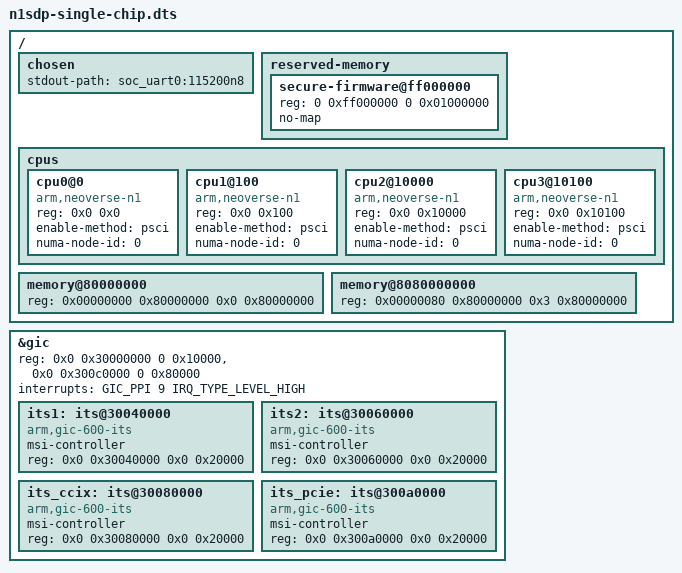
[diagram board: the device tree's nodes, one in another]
/*
 * Copyright (c) 2020, Arm Limited. All rights reserved.
 *
 * SPDX-License-Identifier: BSD-3-Clause
 */

/dts-v1/;

#include "n1sdp.dtsi"

/ {

	chosen {
		stdout-path = "soc_uart0:115200n8";
	};

	reserved-memory {
		#address-cells = <2>;
		#size-cells = <2>;
		ranges;

		secure-firmware@ff000000 {
			reg = <0 0xff000000 0 0x01000000>;
			no-map;
		};
	};

	cpus {
		#address-cells = <2>;
		#size-cells = <0>;
		cpu0@0 {
			compatible = "arm,neoverse-n1";
			reg = <0x0 0x0>;
			device_type = "cpu";
			enable-method = "psci";
			/* node 0 */
			numa-node-id = <0>;
		};
		cpu1@100 {
			compatible = "arm,neoverse-n1";
			reg = <0x0 0x100>;
			device_type = "cpu";
			enable-method = "psci";
			/* node 0 */
			numa-node-id = <0>;
		};
		cpu2@10000 {
			compatible = "arm,neoverse-n1";
			reg = <0x0 0x10000>;
			device_type = "cpu";
			enable-method = "psci";
			/* node 0 */
			numa-node-id = <0>;
		};
		cpu3@10100 {
			compatible = "arm,neoverse-n1";
			reg = <0x0 0x10100>;
			device_type = "cpu";
			enable-method = "psci";
			/* node 0 */
			numa-node-id = <0>;
		};
	};

	/* The first bank of memory, memory map is actually provided by UEFI. */
	memory@80000000 {
		#address-cells = <2>;
		#size-cells = <2>;
		device_type = "memory";
		/* [0x80000000-0xffffffff] */
		reg = <0x00000000 0x80000000 0x0 0x80000000>;
	};

	memory@8080000000 {
		#address-cells = <2>;
		#size-cells = <2>;
		device_type = "memory";
		/* [0x8080000000-0x83ffffffff] */
		reg = <0x00000080 0x80000000 0x3 0x80000000>;
	};

};

&gic {
	reg = <0x0 0x30000000 0 0x10000>,	/* GICD */
	      <0x0 0x300c0000 0 0x80000>;	/* GICR */
	interrupts = <GIC_PPI 9 IRQ_TYPE_LEVEL_HIGH>;

	its1: its@30040000 {
		compatible = "arm,gic-600-its", "arm,gic-v3-its";
		msi-controller;
		#msi-cells = <1>;
		reg = <0x0 0x30040000 0x0 0x20000>;
	};

	its2: its@30060000 {
		compatible = "arm,gic-600-its", "arm,gic-v3-its";
		msi-controller;
		#msi-cells = <1>;
		reg = <0x0 0x30060000 0x0 0x20000>;
	};

	its_ccix: its@30080000 {
		compatible = "arm,gic-600-its", "arm,gic-v3-its";
		msi-controller;
		#msi-cells = <1>;
		reg = <0x0 0x30080000 0x0 0x20000>;
	};

	its_pcie: its@300a0000 {
		compatible = "arm,gic-600-its", "arm,gic-v3-its";
		msi-controller;
		#msi-cells = <1>;
		reg = <0x0 0x300a0000 0x0 0x20000>;
	};
};
